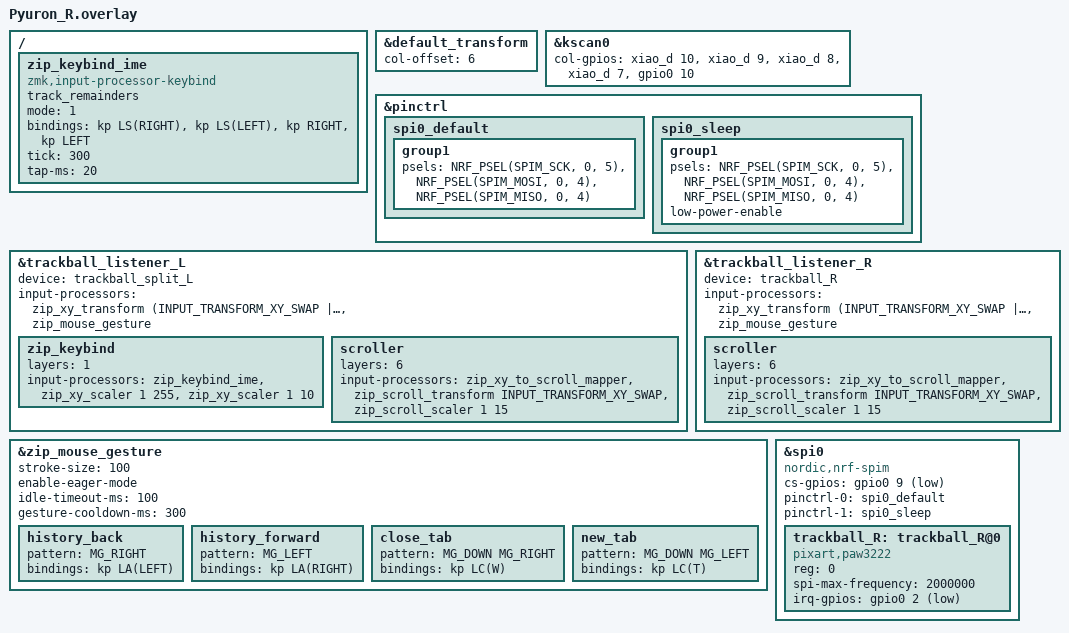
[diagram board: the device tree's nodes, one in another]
#include <mouse-gesture.dtsi>
#include <input/processors/zmk-input-processor-keybind.dtsi>
#include <zephyr/dt-bindings/input/input-event-codes.h>
#include <dt-bindings/zmk/input_transform.h>
#include <input/processors.dtsi>
#include <dt-bindings/zmk/bt.h>
#include <dt-bindings/zmk/keys.h>
#include "Pyuron.dtsi"

/* あなたの環境の実測値に基づく独自定義 gestuer_mouse用 */
#define MG_UP    1
#define MG_DOWN  2
#define MG_RIGHT 8
#define MG_LEFT  4

&default_transform {
    col-offset = <6>;
};

&kscan0 {
    col-gpios = <&xiao_d 10 GPIO_ACTIVE_HIGH>,
                <&xiao_d 9 GPIO_ACTIVE_HIGH>,
                <&xiao_d 8 GPIO_ACTIVE_HIGH>,
                <&xiao_d 7 GPIO_ACTIVE_HIGH>,
                <&gpio0 10 GPIO_ACTIVE_HIGH>;
};

&pinctrl {
    spi0_default: spi0_default {
        group1 {
            psels = <NRF_PSEL(SPIM_SCK, 0, 5)>,
                    <NRF_PSEL(SPIM_MOSI, 0, 4)>,
                    <NRF_PSEL(SPIM_MISO, 0, 4)>;
        };
    };

    spi0_sleep: spi0_sleep {
        group1 {
            psels = <NRF_PSEL(SPIM_SCK, 0, 5)>,
                    <NRF_PSEL(SPIM_MOSI, 0, 4)>,
                    <NRF_PSEL(SPIM_MISO, 0, 4)>;
            low-power-enable;
        };
    };
};

/*
&zip_mouse_gesture {
    status = "okay";
    stroke-size = <100>;
    idle-timeout-ms = <100>;
    gesture-cooldown-ms = <300>;

    change_int4 {
        pattern = <MG_LEFT>;
        bindings = <&kp INT4>;
    };
    change_int5 {
        pattern = <MG_RIGHT>;
        bindings = <&kp INT5>;
    };
};
*/


/ {
    zip_keybind_ime: zip_keybind_ime {
        compatible = "zmk,input-processor-keybind";
        #input-processor-cells = <0>;
        track_remainders;
        mode = <1>; // 4方向モード

        // 上下左右の割り当て
        // 1: 下（文節を伸長）
        // 2: 上（文節を短縮）
        // 3: 右（文節右移動）
        // 4: 左（文節左移動）
        bindings = <&kp LS(RIGHT)>, <&kp LS(LEFT)>, <&kp RIGHT>, <&kp LEFT>;
        tick = <300>;   // 1入力あたりの回転量
        tap-ms = <20>;
    };
};

/* Pyuron.dtsiでスクロールに設定したものをトラックボールマウスに再設定 */
&trackball_listener_L {
    status = "okay";
    device = <&trackball_split_L>;
    input-processors = 
        <&zip_xy_transform (INPUT_TRANSFORM_XY_SWAP | INPUT_TRANSFORM_X_INVERT)>,
        <&zip_mouse_gesture>;

    zip_keybind {
        layers = <1>; 
        input-processors = 
                           <&zip_keybind_ime>,
                           <&zip_xy_scaler 1 255>,
                           <&zip_xy_scaler 1 10>;
                       
    };

    scroller {
        layers = <6>;
        input-processors = 
                           <&zip_xy_to_scroll_mapper>, 
                           <&zip_scroll_transform INPUT_TRANSFORM_XY_SWAP>,
                           <&zip_scroll_scaler 1 15>;
    };
};

&trackball_listener_R {
    status = "okay";
    device = <&trackball_R>;
// 【重要】右側でもマウスを動かすための基本設定を追加
    // もしこれでも向きが逆なら、ここにある SWAP や INVERT を外すなどして調整します
    input-processors = <&zip_xy_transform (INPUT_TRANSFORM_XY_SWAP | INPUT_TRANSFORM_Y_INVERT)>,
                       <&zip_mouse_gesture>;

    scroller {
        layers = <6>;
        input-processors = 
                           <&zip_xy_to_scroll_mapper>, 
                           <&zip_scroll_transform INPUT_TRANSFORM_XY_SWAP>,
                           <&zip_scroll_scaler 1 15>;
    };
};

&zip_mouse_gesture {
    status = "okay";
    stroke-size = <100>;
    enable-eager-mode;
    idle-timeout-ms = <100>;
    gesture-cooldown-ms = <300>;

    history_back {
        pattern = <MG_RIGHT>;
        bindings = <&kp LA(LEFT)>;
    };

    history_forward {
        pattern = <MG_LEFT>;
        bindings = <&kp LA(RIGHT)>;
    };

    close_tab {
        pattern = <MG_DOWN MG_RIGHT>;
        bindings = <&kp LC(W)>;
    };

    new_tab {
        pattern = <MG_DOWN MG_LEFT>;
        bindings = <&kp LC(T)>;
    };
};



&spi0 {
    status = "okay";
    cs-gpios = <&gpio0 9 GPIO_ACTIVE_LOW>;
    pinctrl-0 = <&spi0_default>;
    pinctrl-1 = <&spi0_sleep>;
    pinctrl-names = "default", "sleep";
    compatible = "nordic,nrf-spim";

    trackball_R: trackball_R@0 {
        status = "okay";
        compatible = "pixart,paw3222";
        reg = <0>;
        spi-max-frequency = <2000000>;
        irq-gpios = <&gpio0 2 (GPIO_ACTIVE_LOW | GPIO_PULL_UP)>;
    };
};
